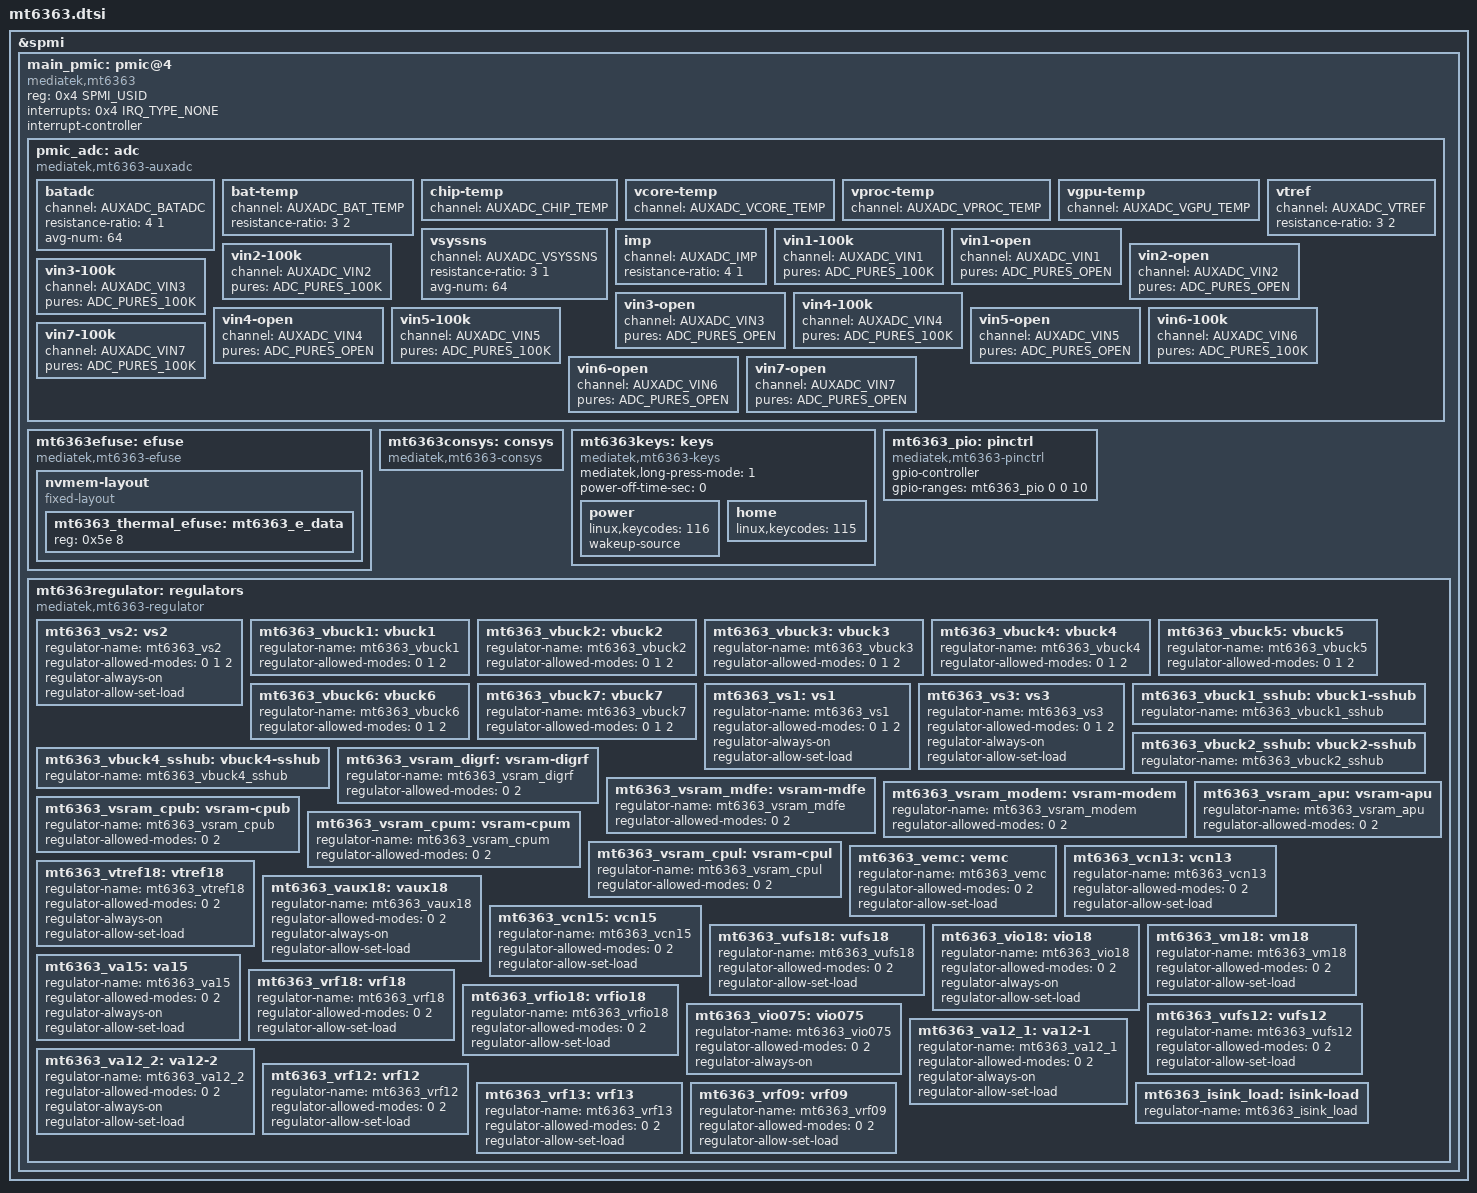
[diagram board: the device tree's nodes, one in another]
// SPDX-License-Identifier: GPL-2.0
/*
 * Copyright (c) 2023 MediaTek Inc.
 */
#include <dt-bindings/iio/mt635x-auxadc.h>
#include <dt-bindings/spmi/spmi.h>

&spmi {
	main_pmic: pmic@4 {
		compatible = "mediatek,mt6363";
		reg = <0x4 SPMI_USID>;
		interrupts = <0x4 IRQ_TYPE_NONE>;
		#address-cells = <0>;
		interrupt-controller;
		#interrupt-cells = <2>;

		pmic_adc: adc {
			compatible = "mediatek,mt6363-auxadc";
			#io-channel-cells = <1>;

			batadc {
				channel = <AUXADC_BATADC>;
				resistance-ratio = <4 1>;
				avg-num = <64>;
			};

			bat-temp {
				channel = <AUXADC_BAT_TEMP>;
				resistance-ratio = <3 2>;
			};

			chip-temp {
				channel = <AUXADC_CHIP_TEMP>;
			};

			vcore-temp {
				channel = <AUXADC_VCORE_TEMP>;
			};

			vproc-temp {
				channel = <AUXADC_VPROC_TEMP>;
			};

			vgpu-temp {
				channel = <AUXADC_VGPU_TEMP>;
			};

			vtref {
				channel = <AUXADC_VTREF>;
				resistance-ratio = <3 2>;
			};

			vsyssns {
				channel = <AUXADC_VSYSSNS>;
				resistance-ratio = <3 1>;
				avg-num = <64>;
			};

			imp {
				channel = <AUXADC_IMP>;
				resistance-ratio = <4 1>;
			};

			vin1-100k {
				channel = <AUXADC_VIN1>;
				pures = <ADC_PURES_100K>;
			};

			vin1-open {
				channel = <AUXADC_VIN1>;
				pures = <ADC_PURES_OPEN>;
			};

			vin2-100k {
				channel = <AUXADC_VIN2>;
				pures = <ADC_PURES_100K>;
			};

			vin2-open {
				channel = <AUXADC_VIN2>;
				pures = <ADC_PURES_OPEN>;
			};

			vin3-100k {
				channel = <AUXADC_VIN3>;
				pures = <ADC_PURES_100K>;
			};

			vin3-open {
				channel = <AUXADC_VIN3>;
				pures = <ADC_PURES_OPEN>;
			};

			vin4-100k {
				channel = <AUXADC_VIN4>;
				pures = <ADC_PURES_100K>;
			};

			vin4-open {
				channel = <AUXADC_VIN4>;
				pures = <ADC_PURES_OPEN>;
			};

			vin5-100k {
				channel = <AUXADC_VIN5>;
				pures = <ADC_PURES_100K>;
			};

			vin5-open {
				channel = <AUXADC_VIN5>;
				pures = <ADC_PURES_OPEN>;
			};

			vin6-100k {
				channel = <AUXADC_VIN6>;
				pures = <ADC_PURES_100K>;
			};

			vin6-open {
				channel = <AUXADC_VIN6>;
				pures = <ADC_PURES_OPEN>;
			};

			vin7-100k {
				channel = <AUXADC_VIN7>;
				pures = <ADC_PURES_100K>;
			};

			vin7-open {
				channel = <AUXADC_VIN7>;
				pures = <ADC_PURES_OPEN>;
			};
		};

		mt6363efuse: efuse {
			compatible = "mediatek,mt6363-efuse";

			nvmem-layout {
				compatible = "fixed-layout";
				#address-cells = <1>;
				#size-cells = <1>;

				mt6363_thermal_efuse: mt6363_e_data {
					reg = <0x5e 8>;
				};
			};
		};

		mt6363consys: consys {
			compatible = "mediatek,mt6363-consys";
		};

		mt6363keys: keys {
			compatible = "mediatek,mt6363-keys";
			mediatek,long-press-mode = <1>;
			power-off-time-sec = <0>;

			power {
				linux,keycodes = <116>;
				wakeup-source;
			};

			home {
				linux,keycodes = <115>;
			};
		};

		mt6363_pio: pinctrl {
			compatible = "mediatek,mt6363-pinctrl";
			gpio-controller;
			#gpio-cells = <2>;
			gpio-ranges = <&mt6363_pio 0 0 10>;
		};

		mt6363regulator: regulators {
			compatible = "mediatek,mt6363-regulator";

			mt6363_vs2: vs2 {
				regulator-name = "mt6363_vs2";
				regulator-allowed-modes = <0 1 2>;
				regulator-always-on;
				regulator-allow-set-load;
			};

			mt6363_vbuck1: vbuck1 {
				regulator-name = "mt6363_vbuck1";
				regulator-allowed-modes = <0 1 2>;
			};

			mt6363_vbuck2: vbuck2 {
				regulator-name = "mt6363_vbuck2";
				regulator-allowed-modes = <0 1 2>;
			};

			mt6363_vbuck3: vbuck3 {
				regulator-name = "mt6363_vbuck3";
				regulator-allowed-modes = <0 1 2>;
			};

			mt6363_vbuck4: vbuck4 {
				regulator-name = "mt6363_vbuck4";
				regulator-allowed-modes = <0 1 2>;
			};

			mt6363_vbuck5: vbuck5 {
				regulator-name = "mt6363_vbuck5";
				regulator-allowed-modes = <0 1 2>;
			};

			mt6363_vbuck6: vbuck6 {
				regulator-name = "mt6363_vbuck6";
				regulator-allowed-modes = <0 1 2>;
			};

			mt6363_vbuck7: vbuck7 {
				regulator-name = "mt6363_vbuck7";
				regulator-allowed-modes = <0 1 2>;
			};

			mt6363_vs1: vs1 {
				regulator-name = "mt6363_vs1";
				regulator-allowed-modes = <0 1 2>;
				regulator-always-on;
				regulator-allow-set-load;
			};

			mt6363_vs3: vs3 {
				regulator-name = "mt6363_vs3";
				regulator-allowed-modes = <0 1 2>;
				regulator-always-on;
				regulator-allow-set-load;
			};

			mt6363_vbuck1_sshub: vbuck1-sshub {
				regulator-name = "mt6363_vbuck1_sshub";
			};

			mt6363_vbuck2_sshub: vbuck2-sshub {
				regulator-name = "mt6363_vbuck2_sshub";
			};

			mt6363_vbuck4_sshub: vbuck4-sshub {
				regulator-name = "mt6363_vbuck4_sshub";
			};

			mt6363_vsram_digrf: vsram-digrf {
				regulator-name = "mt6363_vsram_digrf";
				regulator-allowed-modes = <0 2>;
			};

			mt6363_vsram_mdfe: vsram-mdfe {
				regulator-name = "mt6363_vsram_mdfe";
				regulator-allowed-modes = <0 2>;
			};

			mt6363_vsram_modem: vsram-modem {
				regulator-name = "mt6363_vsram_modem";
				regulator-allowed-modes = <0 2>;
			};

			mt6363_vsram_cpub: vsram-cpub {
				regulator-name = "mt6363_vsram_cpub";
				regulator-allowed-modes = <0 2>;
			};

			mt6363_vsram_cpum: vsram-cpum {
				regulator-name = "mt6363_vsram_cpum";
				regulator-allowed-modes = <0 2>;
			};

			mt6363_vsram_cpul: vsram-cpul {
				regulator-name = "mt6363_vsram_cpul";
				regulator-allowed-modes = <0 2>;
			};

			mt6363_vsram_apu: vsram-apu {
				regulator-name = "mt6363_vsram_apu";
				regulator-allowed-modes = <0 2>;
			};

			mt6363_vemc: vemc {
				regulator-name = "mt6363_vemc";
				regulator-allowed-modes = <0 2>;
				regulator-allow-set-load;
			};

			mt6363_vcn13: vcn13 {
				regulator-name = "mt6363_vcn13";
				regulator-allowed-modes = <0 2>;
				regulator-allow-set-load;
			};

			mt6363_vtref18: vtref18 {
				regulator-name = "mt6363_vtref18";
				regulator-allowed-modes = <0 2>;
				regulator-always-on;
				regulator-allow-set-load;
			};

			mt6363_vaux18: vaux18 {
				regulator-name = "mt6363_vaux18";
				regulator-allowed-modes = <0 2>;
				regulator-always-on;
				regulator-allow-set-load;
			};

			mt6363_vcn15: vcn15 {
				regulator-name = "mt6363_vcn15";
				regulator-allowed-modes = <0 2>;
				regulator-allow-set-load;
			};

			mt6363_vufs18: vufs18 {
				regulator-name = "mt6363_vufs18";
				regulator-allowed-modes = <0 2>;
				regulator-allow-set-load;
			};

			mt6363_vio18: vio18 {
				regulator-name = "mt6363_vio18";
				regulator-allowed-modes = <0 2>;
				regulator-always-on;
				regulator-allow-set-load;
			};

			mt6363_vm18: vm18 {
				regulator-name = "mt6363_vm18";
				regulator-allowed-modes = <0 2>;
				regulator-allow-set-load;
			};

			mt6363_va15: va15 {
				regulator-name = "mt6363_va15";
				regulator-allowed-modes = <0 2>;
				regulator-always-on;
				regulator-allow-set-load;
			};

			mt6363_vrf18: vrf18 {
				regulator-name = "mt6363_vrf18";
				regulator-allowed-modes = <0 2>;
				regulator-allow-set-load;
			};

			mt6363_vrfio18: vrfio18 {
				regulator-name = "mt6363_vrfio18";
				regulator-allowed-modes = <0 2>;
				regulator-allow-set-load;
			};

			mt6363_vio075: vio075 {
				regulator-name = "mt6363_vio075";
				regulator-allowed-modes = <0 2>;
				regulator-always-on;
			};

			mt6363_vufs12: vufs12 {
				regulator-name = "mt6363_vufs12";
				regulator-allowed-modes = <0 2>;
				regulator-allow-set-load;
			};

			mt6363_va12_1: va12-1 {
				regulator-name = "mt6363_va12_1";
				regulator-allowed-modes = <0 2>;
				regulator-always-on;
				regulator-allow-set-load;
			};

			mt6363_va12_2: va12-2 {
				regulator-name = "mt6363_va12_2";
				regulator-allowed-modes = <0 2>;
				regulator-always-on;
				regulator-allow-set-load;
			};

			mt6363_vrf12: vrf12 {
				regulator-name = "mt6363_vrf12";
				regulator-allowed-modes = <0 2>;
				regulator-allow-set-load;
			};

			mt6363_vrf13: vrf13 {
				regulator-name = "mt6363_vrf13";
				regulator-allowed-modes = <0 2>;
				regulator-allow-set-load;
			};

			mt6363_vrf09: vrf09 {
				regulator-name = "mt6363_vrf09";
				regulator-allowed-modes = <0 2>;
				regulator-allow-set-load;
			};

			mt6363_isink_load: isink-load {
				regulator-name = "mt6363_isink_load";
			};
		};
	};
};
